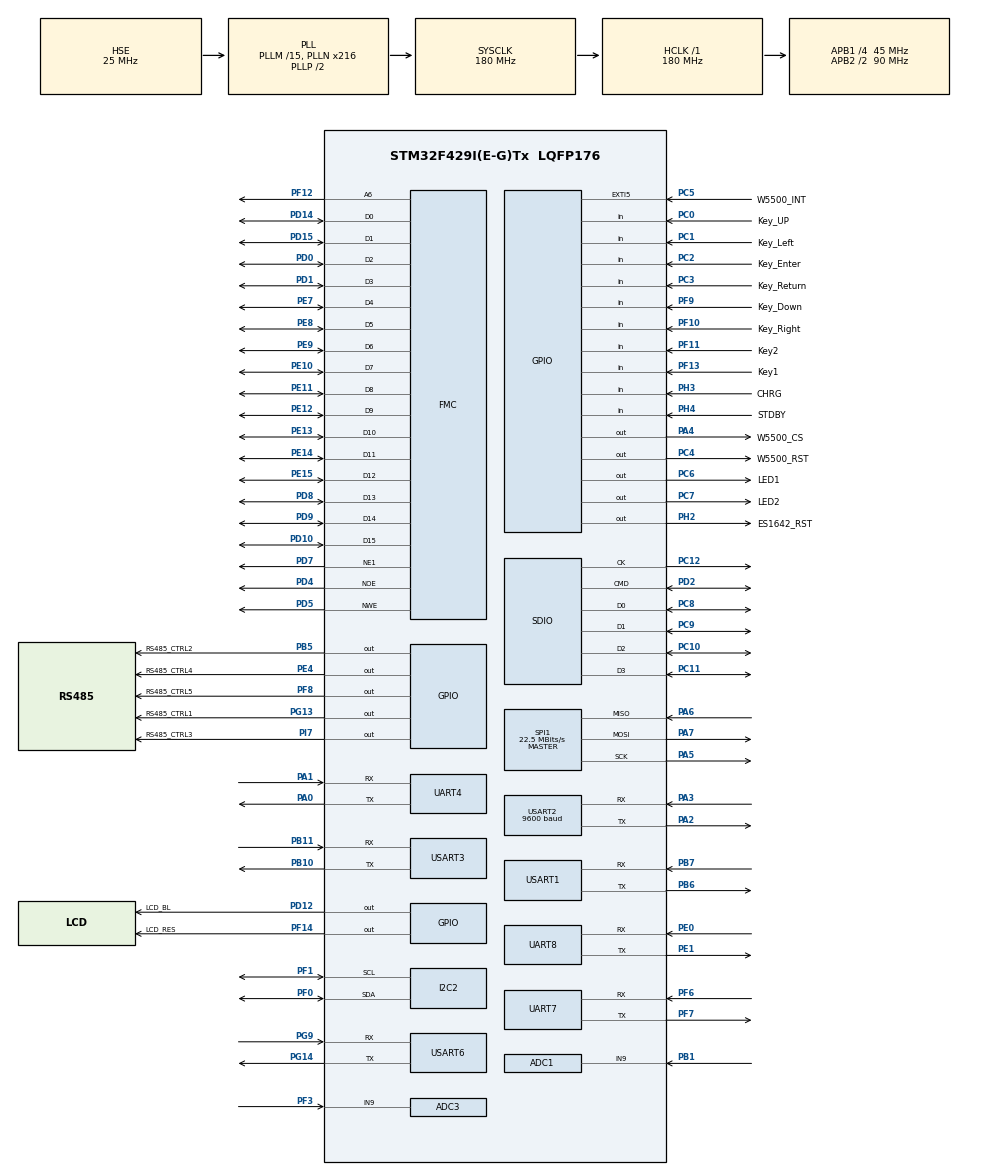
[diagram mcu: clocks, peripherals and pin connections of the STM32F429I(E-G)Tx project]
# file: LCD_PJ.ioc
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ADC1.Channel-1\#ChannelRegularConversion=ADC_CHANNEL_9
ADC1.NbrOfConversionFlag=1
ADC1.Rank-1\#ChannelRegularConversion=1
ADC1.SamplingTime-1\#ChannelRegularConversion=ADC_SAMPLETIME_144CYCLES
ADC1.master=1
ADC3.Channel-0\#ChannelRegularConversion=ADC_CHANNEL_9
ADC3.NbrOfConversionFlag=1
ADC3.Rank-0\#ChannelRegularConversion=1
ADC3.SamplingTime-0\#ChannelRegularConversion=ADC_SAMPLETIME_144CYCLES
Dma.MEMTOMEM.2.Direction=DMA_MEMORY_TO_MEMORY
Dma.MEMTOMEM.2.FIFOMode=DMA_FIFOMODE_ENABLE
Dma.MEMTOMEM.2.FIFOThreshold=DMA_FIFO_THRESHOLD_FULL
Dma.MEMTOMEM.2.Instance=DMA2_Stream4
Dma.MEMTOMEM.2.MemBurst=DMA_MBURST_INC8
Dma.MEMTOMEM.2.MemDataAlignment=DMA_MDATAALIGN_HALFWORD
Dma.MEMTOMEM.2.MemInc=DMA_MINC_DISABLE
Dma.MEMTOMEM.2.Mode=DMA_NORMAL
Dma.MEMTOMEM.2.PeriphBurst=DMA_PBURST_INC8
Dma.MEMTOMEM.2.PeriphDataAlignment=DMA_PDATAALIGN_HALFWORD
Dma.MEMTOMEM.2.PeriphInc=DMA_PINC_ENABLE
Dma.MEMTOMEM.2.Priority=DMA_PRIORITY_LOW
Dma.Request0=SDIO_RX
Dma.Request1=SDIO_TX
Dma.Request10=USART2_TX
Dma.Request11=SPI1_RX
Dma.Request12=SPI1_TX
Dma.Request2=MEMTOMEM
Dma.Request3=USART2_RX
Dma.Request4=USART3_RX
Dma.Request5=USART3_TX
Dma.Request6=USART6_RX
Dma.Request7=USART1_RX
Dma.Request8=UART4_RX
Dma.Request9=UART7_RX
Dma.SDIO_RX.0.Direction=DMA_PERIPH_TO_MEMORY
Dma.SDIO_RX.0.FIFOMode=DMA_FIFOMODE_ENABLE
Dma.SDIO_RX.0.FIFOThreshold=DMA_FIFO_THRESHOLD_FULL
Dma.SDIO_RX.0.Instance=DMA2_Stream6
Dma.SDIO_RX.0.MemBurst=DMA_MBURST_INC4
Dma.SDIO_RX.0.MemDataAlignment=DMA_MDATAALIGN_WORD
Dma.SDIO_RX.0.MemInc=DMA_MINC_ENABLE
Dma.SDIO_RX.0.Mode=DMA_PFCTRL
Dma.SDIO_RX.0.PeriphBurst=DMA_PBURST_INC4
Dma.SDIO_RX.0.PeriphDataAlignment=DMA_PDATAALIGN_WORD
Dma.SDIO_RX.0.PeriphInc=DMA_PINC_DISABLE
Dma.SDIO_RX.0.Priority=DMA_PRIORITY_MEDIUM
Dma.SDIO_TX.1.Direction=DMA_MEMORY_TO_PERIPH
Dma.SDIO_TX.1.FIFOMode=DMA_FIFOMODE_ENABLE
Dma.SDIO_TX.1.FIFOThreshold=DMA_FIFO_THRESHOLD_FULL
Dma.SDIO_TX.1.Instance=DMA2_Stream3
Dma.SDIO_TX.1.MemBurst=DMA_MBURST_INC4
Dma.SDIO_TX.1.MemDataAlignment=DMA_MDATAALIGN_WORD
Dma.SDIO_TX.1.MemInc=DMA_MINC_ENABLE
Dma.SDIO_TX.1.Mode=DMA_PFCTRL
Dma.SDIO_TX.1.PeriphBurst=DMA_PBURST_INC4
Dma.SDIO_TX.1.PeriphDataAlignment=DMA_PDATAALIGN_WORD
Dma.SDIO_TX.1.PeriphInc=DMA_PINC_DISABLE
Dma.SDIO_TX.1.Priority=DMA_PRIORITY_MEDIUM
Dma.SPI1_RX.11.Direction=DMA_PERIPH_TO_MEMORY
Dma.SPI1_RX.11.FIFOMode=DMA_FIFOMODE_DISABLE
Dma.SPI1_RX.11.Instance=DMA2_Stream0
Dma.SPI1_RX.11.MemDataAlignment=DMA_MDATAALIGN_BYTE
Dma.SPI1_RX.11.MemInc=DMA_MINC_ENABLE
Dma.SPI1_RX.11.Mode=DMA_NORMAL
Dma.SPI1_RX.11.PeriphDataAlignment=DMA_PDATAALIGN_BYTE
Dma.SPI1_RX.11.PeriphInc=DMA_PINC_DISABLE
Dma.SPI1_RX.11.Priority=DMA_PRIORITY_LOW
Dma.SPI1_TX.12.Direction=DMA_MEMORY_TO_PERIPH
Dma.SPI1_TX.12.FIFOMode=DMA_FIFOMODE_DISABLE
Dma.SPI1_TX.12.Instance=DMA2_Stream5
Dma.SPI1_TX.12.MemDataAlignment=DMA_MDATAALIGN_BYTE
Dma.SPI1_TX.12.MemInc=DMA_MINC_ENABLE
Dma.SPI1_TX.12.Mode=DMA_NORMAL
Dma.SPI1_TX.12.PeriphDataAlignment=DMA_PDATAALIGN_BYTE
Dma.SPI1_TX.12.PeriphInc=DMA_PINC_DISABLE
Dma.SPI1_TX.12.Priority=DMA_PRIORITY_LOW
Dma.UART4_RX.8.Direction=DMA_PERIPH_TO_MEMORY
Dma.UART4_RX.8.FIFOMode=DMA_FIFOMODE_DISABLE
Dma.UART4_RX.8.Instance=DMA1_Stream2
Dma.UART4_RX.8.MemDataAlignment=DMA_MDATAALIGN_BYTE
Dma.UART4_RX.8.MemInc=DMA_MINC_ENABLE
Dma.UART4_RX.8.Mode=DMA_NORMAL
Dma.UART4_RX.8.PeriphDataAlignment=DMA_PDATAALIGN_BYTE
Dma.UART4_RX.8.PeriphInc=DMA_PINC_DISABLE
Dma.UART4_RX.8.Priority=DMA_PRIORITY_LOW
Dma.UART7_RX.9.Direction=DMA_PERIPH_TO_MEMORY
Dma.UART7_RX.9.FIFOMode=DMA_FIFOMODE_DISABLE
Dma.UART7_RX.9.Instance=DMA1_Stream3
Dma.UART7_RX.9.MemDataAlignment=DMA_MDATAALIGN_BYTE
Dma.UART7_RX.9.MemInc=DMA_MINC_ENABLE
Dma.UART7_RX.9.Mode=DMA_NORMAL
Dma.UART7_RX.9.PeriphDataAlignment=DMA_PDATAALIGN_BYTE
Dma.UART7_RX.9.PeriphInc=DMA_PINC_DISABLE
Dma.UART7_RX.9.Priority=DMA_PRIORITY_LOW
Dma.USART1_RX.7.Direction=DMA_PERIPH_TO_MEMORY
Dma.USART1_RX.7.FIFOMode=DMA_FIFOMODE_DISABLE
Dma.USART1_RX.7.Instance=DMA2_Stream2
Dma.USART1_RX.7.MemDataAlignment=DMA_MDATAALIGN_BYTE
Dma.USART1_RX.7.MemInc=DMA_MINC_ENABLE
Dma.USART1_RX.7.Mode=DMA_NORMAL
Dma.USART1_RX.7.PeriphDataAlignment=DMA_PDATAALIGN_BYTE
Dma.USART1_RX.7.PeriphInc=DMA_PINC_DISABLE
Dma.USART1_RX.7.Priority=DMA_PRIORITY_LOW
Dma.USART2_RX.3.Direction=DMA_PERIPH_TO_MEMORY
Dma.USART2_RX.3.FIFOMode=DMA_FIFOMODE_DISABLE
Dma.USART2_RX.3.Instance=DMA1_Stream5
Dma.USART2_RX.3.MemDataAlignment=DMA_MDATAALIGN_BYTE
Dma.USART2_RX.3.MemInc=DMA_MINC_ENABLE
Dma.USART2_RX.3.Mode=DMA_NORMAL
Dma.USART2_RX.3.PeriphDataAlignment=DMA_PDATAALIGN_BYTE
Dma.USART2_RX.3.PeriphInc=DMA_PINC_DISABLE
Dma.USART2_RX.3.Priority=DMA_PRIORITY_LOW
Dma.USART2_TX.10.Direction=DMA_MEMORY_TO_PERIPH
Dma.USART2_TX.10.FIFOMode=DMA_FIFOMODE_DISABLE
Dma.USART2_TX.10.Instance=DMA1_Stream6
Dma.USART2_TX.10.MemDataAlignment=DMA_MDATAALIGN_BYTE
Dma.USART2_TX.10.MemInc=DMA_MINC_ENABLE
Dma.USART2_TX.10.Mode=DMA_NORMAL
Dma.USART2_TX.10.PeriphDataAlignment=DMA_PDATAALIGN_BYTE
Dma.USART2_TX.10.PeriphInc=DMA_PINC_DISABLE
Dma.USART2_TX.10.Priority=DMA_PRIORITY_LOW
Dma.USART3_RX.4.Direction=DMA_PERIPH_TO_MEMORY
Dma.USART3_RX.4.FIFOMode=DMA_FIFOMODE_DISABLE
Dma.USART3_RX.4.Instance=DMA1_Stream1
Dma.USART3_RX.4.MemDataAlignment=DMA_MDATAALIGN_BYTE
Dma.USART3_RX.4.MemInc=DMA_MINC_ENABLE
Dma.USART3_RX.4.Mode=DMA_NORMAL
Dma.USART3_RX.4.PeriphDataAlignment=DMA_PDATAALIGN_BYTE
Dma.USART3_RX.4.PeriphInc=DMA_PINC_DISABLE
Dma.USART3_RX.4.Priority=DMA_PRIORITY_LOW
Dma.USART3_TX.5.Direction=DMA_MEMORY_TO_PERIPH
Dma.USART3_TX.5.FIFOMode=DMA_FIFOMODE_DISABLE
Dma.USART3_TX.5.Instance=DMA1_Stream4
Dma.USART3_TX.5.MemDataAlignment=DMA_MDATAALIGN_BYTE
Dma.USART3_TX.5.MemInc=DMA_MINC_ENABLE
Dma.USART3_TX.5.Mode=DMA_NORMAL
Dma.USART3_TX.5.PeriphDataAlignment=DMA_PDATAALIGN_BYTE
Dma.USART3_TX.5.PeriphInc=DMA_PINC_DISABLE
Dma.USART3_TX.5.Priority=DMA_PRIORITY_LOW
Dma.USART6_RX.6.Direction=DMA_PERIPH_TO_MEMORY
Dma.USART6_RX.6.FIFOMode=DMA_FIFOMODE_DISABLE
Dma.USART6_RX.6.Instance=DMA2_Stream1
Dma.USART6_RX.6.MemDataAlignment=DMA_MDATAALIGN_BYTE
Dma.USART6_RX.6.MemInc=DMA_MINC_ENABLE
Dma.USART6_RX.6.Mode=DMA_NORMAL
Dma.USART6_RX.6.PeriphDataAlignment=DMA_PDATAALIGN_BYTE
Dma.USART6_RX.6.PeriphInc=DMA_PINC_DISABLE
Dma.USART6_RX.6.Priority=DMA_PRIORITY_LOW
FATFS._CODE_PAGE=936
FATFS._FS_EXFAT=0
FATFS._MAX_LFN=255
FATFS._MAX_SS=4096
FATFS._USE_LFN=2
FATFS._USE_MUTEX=0
FATFS._USE_TRIM=1
FMC.AddressSetupTime1=1
FMC.BusTurnAroundDuration1=0
FMC.DataSetupTime1=8
FREERTOS.BinarySemaphores01=at_sem,Dynamic,NULL,Depleted;at_mutex,Dynamic,NULL,Available;ES1642_send,Dynamic,NULL,Depleted;ES1642_mutex,Dynamic,NULL,Available
FREERTOS.Tasks01=defaultTask,19,512,StartDefaultTask,Default,NULL,Dynamic,NULL,NULL;LVGLTask,35,1024,lvgl_task,Default,NULL,Dynamic,NULL,NULL;A7680CTask,27,512,A7680C_Task,Default,NULL,Dynamic,NULL,NULL;W5500Task,17,1024,W5500_Task,As external,NULL,Dynamic,NULL,NULL;ES1642Task,29,512,ES1642_Task,Default,NULL,Dynamic,NULL,NULL;RTCTask,23,512,RTC_Task,Default,NULL,Dynamic,NULL,NULL;WeatherTask,13,512,Weather_Task,Default,NULL,Dynamic,NULL,NULL;RS485UARTProces,37,512,RS485_UART_ProcessTask,As external,NULL,Dynamic,NULL,NULL;DevicePollTask,21,640,DevicePoll_Task,Default,NULL,Dynamic,NULL,NULL
FREERTOS.Timers01=weatherTimer,Callback01,osTimerOnce,Default,NULL,Dynamic,NULL
FREERTOS.configTOTAL_HEAP_SIZE=30720
FREERTOS.configUSE_TICK_HOOK=1
IWDG.Prescaler=IWDG_PRESCALER_256
Mcu.Family=STM32F4
Mcu.Name=STM32F429I(E-G)Tx
Mcu.Package=LQFP176
NVIC.DMA1_Stream1_IRQn=true\:5\:0\:true\:false\:true\:true\:false\:true\:true
NVIC.DMA1_Stream2_IRQn=true\:5\:0\:true\:false\:true\:true\:false\:true\:true
NVIC.DMA1_Stream3_IRQn=true\:5\:0\:true\:false\:true\:true\:false\:true\:true
NVIC.DMA1_Stream4_IRQn=true\:5\:0\:true\:false\:true\:true\:false\:true\:true
NVIC.DMA1_Stream5_IRQn=true\:5\:0\:true\:false\:true\:true\:false\:true\:true
NVIC.DMA1_Stream6_IRQn=true\:5\:0\:false\:false\:true\:true\:false\:true\:true
NVIC.DMA2_Stream0_IRQn=true\:5\:0\:false\:false\:true\:true\:true\:true\:true
NVIC.DMA2_Stream1_IRQn=true\:5\:0\:true\:false\:true\:true\:false\:true\:true
NVIC.DMA2_Stream2_IRQn=true\:5\:0\:true\:false\:true\:true\:false\:true\:true
NVIC.DMA2_Stream3_IRQn=true\:5\:0\:true\:false\:true\:true\:false\:true\:true
NVIC.DMA2_Stream4_IRQn=true\:5\:0\:true\:false\:true\:true\:true\:true\:true
NVIC.DMA2_Stream5_IRQn=true\:5\:0\:false\:false\:true\:true\:false\:true\:true
NVIC.DMA2_Stream6_IRQn=true\:5\:0\:true\:false\:true\:true\:false\:true\:true
NVIC.EXTI9_5_IRQn=true\:5\:0\:true\:false\:true\:true\:true\:true\:true
NVIC.PriorityGroup=NVIC_PRIORITYGROUP_4
NVIC.SDIO_IRQn=true\:5\:0\:true\:false\:true\:true\:true\:true\:true
NVIC.SPI1_IRQn=true\:5\:0\:true\:false\:true\:true\:true\:true\:true
NVIC.TIM2_IRQn=true\:6\:0\:true\:false\:true\:true\:true\:true\:true
NVIC.TIM3_IRQn=true\:5\:0\:false\:false\:true\:true\:true\:true\:true
NVIC.TIM6_DAC_IRQn=true\:15\:0\:false\:false\:true\:false\:false\:true\:true
NVIC.TimeBase=TIM6_DAC_IRQn
NVIC.TimeBaseIP=TIM6
NVIC.UART4_IRQn=true\:5\:0\:true\:false\:true\:true\:true\:true\:true
NVIC.UART7_IRQn=true\:5\:0\:false\:false\:true\:true\:true\:true\:true
NVIC.UART8_IRQn=true\:5\:0\:true\:false\:true\:true\:true\:true\:true
NVIC.USART1_IRQn=true\:5\:0\:true\:false\:true\:true\:true\:true\:true
NVIC.USART2_IRQn=true\:5\:0\:true\:false\:true\:true\:true\:true\:true
NVIC.USART3_IRQn=true\:5\:0\:true\:false\:true\:true\:true\:true\:true
NVIC.USART6_IRQn=true\:5\:0\:true\:false\:true\:true\:true\:true\:true
PA0/WKUP.Mode=Asynchronous
PA0/WKUP.Signal=UART4_TX
PA1.Mode=Asynchronous
PA1.Signal=UART4_RX
PA13.Mode=Serial_Wire
PA13.Signal=SYS_JTMS-SWDIO
PA14.Mode=Serial_Wire
PA14.Signal=SYS_JTCK-SWCLK
PA2.Mode=Asynchronous
PA2.Signal=USART2_TX
PA3.Mode=Asynchronous
PA3.Signal=USART2_RX
PA4.GPIO_Label=W5500_CS
PA4.GPIO_Speed=GPIO_SPEED_FREQ_HIGH
PA4.PinState=GPIO_PIN_SET
PA4.Signal=GPIO_Output
PA5.Mode=Full_Duplex_Master
PA5.Signal=SPI1_SCK
PA6.Mode=Full_Duplex_Master
PA6.Signal=SPI1_MISO
PA7.Mode=Full_Duplex_Master
PA7.Signal=SPI1_MOSI
PB1.Signal=ADCx_IN9
PB10.Mode=Asynchronous
PB10.Signal=USART3_TX
PB11.Mode=Asynchronous
PB11.Signal=USART3_RX
PB5.GPIO_Label=RS485_CTRL2
PB5.GPIO_Speed=GPIO_SPEED_FREQ_HIGH
PB5.Signal=GPIO_Output
PB6.Mode=Asynchronous
PB6.Signal=USART1_TX
PB7.Mode=Asynchronous
PB7.Signal=USART1_RX
PC0.GPIO_Label=Key_UP
PC0.GPIO_PuPd=GPIO_PULLUP
PC0.Signal=GPIO_Input
PC1.GPIO_Label=Key_Left
PC1.GPIO_PuPd=GPIO_PULLUP
PC1.Signal=GPIO_Input
PC10.GPIO_PuPd=GPIO_PULLUP
PC10.Mode=SD_4_bits_Wide_bus
PC10.Signal=SDIO_D2
PC11.GPIO_PuPd=GPIO_PULLUP
PC11.Mode=SD_4_bits_Wide_bus
PC11.Signal=SDIO_D3
PC12.Mode=SD_4_bits_Wide_bus
PC12.Signal=SDIO_CK
PC14/OSC32_IN.Mode=LSE-External-Oscillator
PC14/OSC32_IN.Signal=RCC_OSC32_IN
PC15/OSC32_OUT.Mode=LSE-External-Oscillator
PC15/OSC32_OUT.Signal=RCC_OSC32_OUT
PC2.GPIO_Label=Key_Enter
PC2.GPIO_PuPd=GPIO_PULLUP
PC2.Signal=GPIO_Input
PC3.GPIO_Label=Key_Return
PC3.GPIO_PuPd=GPIO_PULLUP
PC3.Signal=GPIO_Input
PC4.GPIO_Label=W5500_RST
PC4.GPIO_Speed=GPIO_SPEED_FREQ_HIGH
PC4.PinState=GPIO_PIN_SET
PC4.Signal=GPIO_Output
PC5.GPIO_Label=W5500_INT
PC5.GPIO_ModeDefaultEXTI=GPIO_MODE_IT_FALLING
PC5.GPIO_PuPd=GPIO_PULLUP
PC5.Signal=GPXTI5
PC6.GPIO_Label=LED1
PC6.PinState=GPIO_PIN_SET
PC6.Signal=GPIO_Output
PC7.GPIO_Label=LED2
PC7.GPIO_Speed=GPIO_SPEED_FREQ_HIGH
PC7.PinState=GPIO_PIN_SET
PC7.Signal=GPIO_Output
PC8.GPIO_PuPd=GPIO_PULLUP
PC8.Mode=SD_4_bits_Wide_bus
PC8.Signal=SDIO_D0
PC9.GPIO_PuPd=GPIO_PULLUP
PC9.Mode=SD_4_bits_Wide_bus
PC9.Signal=SDIO_D1
PD0.Signal=FMC_D2_DA2
PD1.Signal=FMC_D3_DA3
PD10.Signal=FMC_D15_DA15
PD12.GPIO_Label=LCD_BL
PD12.GPIO_Speed=GPIO_SPEED_FREQ_HIGH
PD12.Signal=GPIO_Output
PD14.Signal=FMC_D0_DA0
PD15.Signal=FMC_D1_DA1
PD2.GPIO_PuPd=GPIO_PULLUP
PD2.Mode=SD_4_bits_Wide_bus
PD2.Signal=SDIO_CMD
PD4.Signal=FMC_NOE
PD5.Signal=FMC_NWE
PD7.Mode=NorPsramChipSelect1_1
PD7.Signal=FMC_NE1
PD8.Signal=FMC_D13_DA13
PD9.Signal=FMC_D14_DA14
PE0.Mode=Asynchronous
PE0.Signal=UART8_RX
PE1.Mode=Asynchronous
PE1.Signal=UART8_TX
PE10.Signal=FMC_D7_DA7
PE11.Signal=FMC_D8_DA8
PE12.Signal=FMC_D9_DA9
PE13.Signal=FMC_D10_DA10
PE14.Signal=FMC_D11_DA11
PE15.Signal=FMC_D12_DA12
PE4.GPIO_Label=RS485_CTRL4
PE4.Signal=GPIO_Output
PE7.Signal=FMC_D4_DA4
PE8.Signal=FMC_D5_DA5
PE9.Signal=FMC_D6_DA6
PF0.Mode=I2C
PF0.Signal=I2C2_SDA
PF1.Mode=I2C
PF1.Signal=I2C2_SCL
PF10.GPIO_Label=Key_Right
PF10.GPIO_PuPd=GPIO_PULLUP
PF10.Signal=GPIO_Input
PF11.GPIO_Label=Key2
PF11.GPIO_PuPd=GPIO_PULLUP
PF11.Signal=GPIO_Input
PF12.Signal=FMC_A6
PF13.GPIO_Label=Key1
PF13.GPIO_PuPd=GPIO_PULLUP
PF13.Signal=GPIO_Input
PF14.GPIO_Label=LCD_RES
PF14.GPIO_Speed=GPIO_SPEED_FREQ_HIGH
PF14.PinState=GPIO_PIN_SET
PF14.Signal=GPIO_Output
PF3.Mode=IN9
PF3.Signal=ADC3_IN9
PF6.Mode=Asynchronous
PF6.Signal=UART7_RX
PF7.Mode=Asynchronous
PF7.Signal=UART7_TX
PF8.GPIO_Label=RS485_CTRL5
PF8.Signal=GPIO_Output
PF9.GPIO_Label=Key_Down
PF9.GPIO_PuPd=GPIO_PULLUP
PF9.Signal=GPIO_Input
PG13.GPIO_Label=RS485_CTRL1
PG13.GPIO_Speed=GPIO_SPEED_FREQ_HIGH
PG13.Signal=GPIO_Output
PG14.Mode=Asynchronous
PG14.Signal=USART6_TX
PG9.Mode=Asynchronous
PG9.Signal=USART6_RX
PH0/OSC_IN.Mode=HSE-External-Oscillator
PH0/OSC_IN.Signal=RCC_OSC_IN
PH1/OSC_OUT.Mode=HSE-External-Oscillator
PH1/OSC_OUT.Signal=RCC_OSC_OUT
PH2.GPIO_Label=ES1642_RST
PH2.GPIO_Speed=GPIO_SPEED_FREQ_HIGH
PH2.PinState=GPIO_PIN_SET
PH2.Signal=GPIO_Output
PH3.GPIO_Label=CHRG
PH3.GPIO_PuPd=GPIO_PULLUP
PH3.Signal=GPIO_Input
PH4.GPIO_Label=STDBY
PH4.GPIO_PuPd=GPIO_PULLUP
PH4.Signal=GPIO_Input
PI7.GPIO_Label=RS485_CTRL3
PI7.Signal=GPIO_Output
ProjectManager.HeapSize=0x2000
ProjectManager.StackSize=0x4000
ProjectManager.TargetToolchain=MDK-ARM V5.32
RCC.48MHZClocksFreq_Value=45000000
RCC.AHBFreq_Value=180000000
RCC.APB1CLKDivider=RCC_HCLK_DIV4
RCC.APB1Freq_Value=45000000
RCC.APB1TimFreq_Value=90000000
RCC.APB2CLKDivider=RCC_HCLK_DIV2
RCC.APB2Freq_Value=90000000
RCC.APB2TimFreq_Value=180000000
RCC.CortexFreq_Value=180000000
RCC.HCLKFreq_Value=180000000
RCC.HSE_VALUE=25000000
RCC.HSI_VALUE=16000000
RCC.PLLM=15
RCC.PLLN=216
RCC.PLLQ=8
RCC.PLLSAIDivR=RCC_PLLSAIDIVR_4
RCC.PLLSAIN=60
RCC.PLLSourceVirtual=RCC_PLLSOURCE_HSE
RCC.SYSCLKFreq_VALUE=180000000
RCC.SYSCLKSource=RCC_SYSCLKSOURCE_PLLCLK
RCC.VCOOutputFreq_Value=360000000
SDIO.ClockDiv=8
SDIO.HardwareFlowControl=SDIO_HARDWARE_FLOW_CONTROL_DISABLE
SH.ADCx_IN9.0=ADC1_IN9,IN9
SH.FMC_A6.0=FMC_A6,A6_1
SH.FMC_D0_DA0.0=FMC_D0,16b-d1
SH.FMC_D10_DA10.0=FMC_D10,16b-d1
SH.FMC_D11_DA11.0=FMC_D11,16b-d1
SH.FMC_D12_DA12.0=FMC_D12,16b-d1
SH.FMC_D13_DA13.0=FMC_D13,16b-d1
SH.FMC_D14_DA14.0=FMC_D14,16b-d1
SH.FMC_D15_DA15.0=FMC_D15,16b-d1
SH.FMC_D1_DA1.0=FMC_D1,16b-d1
SH.FMC_D2_DA2.0=FMC_D2,16b-d1
SH.FMC_D3_DA3.0=FMC_D3,16b-d1
SH.FMC_D4_DA4.0=FMC_D4,16b-d1
SH.FMC_D5_DA5.0=FMC_D5,16b-d1
SH.FMC_D6_DA6.0=FMC_D6,16b-d1
SH.FMC_D7_DA7.0=FMC_D7,16b-d1
SH.FMC_D8_DA8.0=FMC_D8,16b-d1
SH.FMC_D9_DA9.0=FMC_D9,16b-d1
SH.FMC_NOE.0=FMC_NOE,Lcd1
SH.FMC_NWE.0=FMC_NWE,Lcd1
SPI1.BaudRatePrescaler=SPI_BAUDRATEPRESCALER_4
SPI1.CalculateBaudRate=22.5 MBits/s
SPI1.Direction=SPI_DIRECTION_2LINES
SPI1.Mode=SPI_MODE_MASTER
SPI1.VirtualType=VM_MASTER
TIM2.Period=1000-1
TIM2.Prescaler=90-1
TIM3.Period=59999
TIM3.Prescaler=44999
UART4.VirtualMode=Asynchronous
UART7.VirtualMode=Asynchronous
UART8.VirtualMode=Asynchronous
USART1.VirtualMode=VM_ASYNC
USART2.BaudRate=9600
USART2.VirtualMode=VM_ASYNC
USART3.VirtualMode=VM_ASYNC
USART6.VirtualMode=VM_ASYNC
VP_CRC_VS_CRC.Mode=CRC_Activate
VP_FATFS_VS_SDIO.Mode=SDIO
VP_FREERTOS_VS_CMSIS_V2.Mode=CMSIS_V2
VP_IWDG_VS_IWDG.Mode=IWDG_Activate
VP_RTC_VS_RTC_Activate.Mode=RTC_Enabled
VP_SYS_VS_tim6.Mode=TIM6
VP_TIM2_VS_ClockSourceINT.Mode=Internal
VP_TIM3_VS_ClockSourceINT.Mode=Internal
board=custom

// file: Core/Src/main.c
/* USER CODE BEGIN Header */
/**
  ******************************************************************************
  * @file           : main.c
  * @brief          : Main program body
  ******************************************************************************
  * @attention
  *
  * Copyright (c) 2026 STMicroelectronics.
  * All rights reserved.
  *
  * This software is licensed under terms that can be found in the LICENSE file
  * in the root directory of this software component.
  * If no LICENSE file comes with this software, it is provided AS-IS.
  *
  ******************************************************************************
  */
/* USER CODE END Header */
#include "main.h"
#include "cmsis_os.h"
#include "adc.h"
#include "crc.h"
#include "dma.h"
#include "fatfs.h"
#include "i2c.h"
#include "iwdg.h"
#include "rtc.h"
#include "sdio.h"
#include "spi.h"
#include "tim.h"
#include "usart.h"
#include "gpio.h"
#include "fmc.h"

/* USER CODE BEGIN Includes */
#include "lv_hal_tick.h"
#include "stdio.h"
#include "wiz_interface.h"
#include "lv_port_disp.h"
#include "rs485_usart.h"
#include "battery.h"
#include "bank_switch.h"
#include "ota_upgrade.h"
/* USER CODE END Includes */

void SystemClock_Config(void);
void MX_FREERTOS_Init(void);

int main(void)
{

  /* MCU Configuration--------------------------------------------------------*/

  /* Reset of all peripherals, Initializes the Flash interface and the Systick. */
  HAL_Init();

  /* Configure the system clock */
  SystemClock_Config();

  /* Initialize all configured peripherals */
  MX_GPIO_Init();
  MX_DMA_Init();
  MX_USART1_UART_Init();
  MX_FMC_Init();
  MX_SDIO_SD_Init();
  MX_FATFS_Init();
  MX_SPI1_Init();
  MX_TIM2_Init();
  MX_USART3_UART_Init();
  MX_I2C2_Init();
  MX_USART2_UART_Init();
  MX_TIM3_Init();
  MX_UART4_Init();
  MX_UART7_Init();
  MX_UART8_Init();
  MX_USART6_UART_Init();
  MX_ADC3_Init();
  MX_ADC1_Init();
  MX_CRC_Init();
  MX_IWDG_Init();
  MX_RTC_Init();
  /* USER CODE BEGIN 2 */
	Battery_Init();
	RS485_USART_Init_All();
  /* OTA: check trial boot / rollback (must be after MX_RTC_Init) */
  BANK_EnableDualBank();// 启用双Bank模式 (如果尚未启用)
  OTA_BootCheck();// 回滚检查（如果 magic=PENDING）
  OTA_Init();// 初始化 OTA 状态变量

	Battery_UpdateCache();//更新一次电量缓存
	Solar_UpdateCache();//更新一次太阳能电压缓存
	//注册搬运图像数据完成回调函数
	HAL_DMA_RegisterCallback(&hdma_memtomem_dma2_stream4, HAL_DMA_XFER_CPLT_CB_ID, LVGL_LCD_FSMC_DMA_pCallback);
  /* USER CODE END 2 */

  /* Init scheduler */
  osKernelInitialize();  /* Call init function for freertos objects (in cmsis_os2.c) */
  MX_FREERTOS_Init();

  /* Start scheduler */
  osKernelStart();

  /* We should never get here as control is now taken by the scheduler */

  /* Infinite loop */
  while (1)
  {

  }
}

void SystemClock_Config(void)
{
  RCC_OscInitTypeDef RCC_OscInitStruct = {0};
  RCC_ClkInitTypeDef RCC_ClkInitStruct = {0};

  /** Configure the main internal regulator output voltage
  */
  __HAL_RCC_PWR_CLK_ENABLE();
  __HAL_PWR_VOLTAGESCALING_CONFIG(PWR_REGULATOR_VOLTAGE_SCALE1);

  /** Initializes the RCC Oscillators according to the specified parameters
  * in the RCC_OscInitTypeDef structure.
  */
  RCC_OscInitStruct.OscillatorType = RCC_OSCILLATORTYPE_LSI|RCC_OSCILLATORTYPE_HSE;
  RCC_OscInitStruct.HSEState = RCC_HSE_ON;
  RCC_OscInitStruct.LSIState = RCC_LSI_ON;
  RCC_OscInitStruct.PLL.PLLState = RCC_PLL_ON;
  RCC_OscInitStruct.PLL.PLLSource = RCC_PLLSOURCE_HSE;
  RCC_OscInitStruct.PLL.PLLM = 15;
  RCC_OscInitStruct.PLL.PLLN = 216;
  RCC_OscInitStruct.PLL.PLLP = RCC_PLLP_DIV2;
  RCC_OscInitStruct.PLL.PLLQ = 8;
  if (HAL_RCC_OscConfig(&RCC_OscInitStruct) != HAL_OK)
  {
    Error_Handler();
  }

  /** Activate the Over-Drive mode
  */
  if (HAL_PWREx_EnableOverDrive() != HAL_OK)
  {
    Error_Handler();
  }

  /** Initializes the CPU, AHB and APB buses clocks
  */
  RCC_ClkInitStruct.ClockType = RCC_CLOCKTYPE_HCLK|RCC_CLOCKTYPE_SYSCLK
                              |RCC_CLOCKTYPE_PCLK1|RCC_CLOCKTYPE_PCLK2;
  RCC_ClkInitStruct.SYSCLKSource = RCC_SYSCLKSOURCE_PLLCLK;
  RCC_ClkInitStruct.AHBCLKDivider = RCC_SYSCLK_DIV1;
  RCC_ClkInitStruct.APB1CLKDivider = RCC_HCLK_DIV4;
  RCC_ClkInitStruct.APB2CLKDivider = RCC_HCLK_DIV2;

  if (HAL_RCC_ClockConfig(&RCC_ClkInitStruct, FLASH_LATENCY_5) != HAL_OK)
  {
    Error_Handler();
  }
}

/* USER CODE BEGIN 4 */
void vApplicationTickHook(void)
{
		// 先调用 lv_tick_inc 再调用 lv_task_handler
    lv_tick_inc(1);  // 告诉 LVGL 过了 1 毫秒
}

/* USER CODE END 4 */

void HAL_TIM_PeriodElapsedCallback(TIM_HandleTypeDef *htim)
{
  if (htim->Instance == TIM6)
  {
    HAL_IncTick();
  }
  /* USER CODE BEGIN Callback 1 */
	if (htim->Instance == TIM2)
	{
		wiz_timer_handler();
	}
	if (htim->Instance == TIM3)
	{
		HAL_TIM_Base_Stop_IT(&htim3);//停止定时器,并关闭背光灯
		HAL_GPIO_WritePin(LCD_BL_GPIO_Port, LCD_BL_Pin, GPIO_PIN_RESET);
	}
  /* USER CODE END Callback 1 */
}

void Error_Handler(void)
{
  __disable_irq();
  while (1)
  {
  }
}

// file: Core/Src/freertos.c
/* USER CODE BEGIN Header */
/**
  ******************************************************************************
  * File Name          : freertos.c
  * Description        : Code for freertos applications
  ******************************************************************************
  * @attention
  *
  * Copyright (c) 2026 STMicroelectronics.
  * All rights reserved.
  *
  * This software is licensed under terms that can be found in the LICENSE file
  * in the root directory of this software component.
  * If no LICENSE file comes with this software, it is provided AS-IS.
  *
  ******************************************************************************
  */
/* USER CODE END Header */

#include "FreeRTOS.h"
#include "task.h"
#include "main.h"
#include "cmsis_os.h"

/* USER CODE BEGIN Includes */
#include "stdio.h"
#include "message_buffer.h"
#include "lvgl.h"
#include "lv_port_disp.h"
#include "lv_port_indev.h"
#include "lv_port_fs.h"
#include "key.h"
#include "gui_guider.h"           // Gui Guider 生成的界面和控件的声明
#include "events_init.h"          // Gui Guider 生成的初始化事件、回调函数
#include "sdio.h"
#include "fatfs.h"
#include "custom.h"
#include "a7680c.h"
#include "a7680c_netmgr.h"
#include "a7680c_at.h"
#include "a7680c_mqtt.h"
#include "rx8025t_example.h"
#include "es1642.h"
#include "es1642_usage_guide.h"
#include "device_manager.h"
#include "user_data_manager.h"
#include "a7680c_http.h"
#include "rs485_usart.h"
#include "battery.h"
#include "mppt.h"
#include "user_main.h"
#include "ota_upgrade.h"
#include "tcp_cmd_handler.h"
lv_ui  guider_ui;                     // 定义 界面对象
extern lv_group_t * g_keypad_group;		//声明全局group
WeatherCurrent_t weather_data = {0};//存储天气代码的结构体

/* LVGL互斥锁: 保护多任务对LVGL API的并发访问 */
osMutexId_t lvgl_mutex = NULL;
/* 文件系统互斥锁: 保护共享SDFile/SDFatFS的并发访问 */
osMutexId_t fs_mutex = NULL;
/* USER CODE END Includes */

/* USER CODE BEGIN PTD */
MessageBufferHandle_t uart2Message;//es1642消息缓冲区句柄
MessageBufferHandle_t uart3Message;//a7680c消息缓冲区句柄
/* USER CODE END PTD */

/* USER CODE BEGIN PM */
void SDCardInfo(void)
{
    HAL_SD_CardInfoTypeDef pCardInfo = {0};                    // SD卡信息结构体
    uint8_t status = HAL_SD_GetCardState(&hsd);                // SD卡状态标志值
    if (status == HAL_SD_CARD_TRANSFER)
    {
        HAL_SD_GetCardInfo(&hsd, &pCardInfo);                  // 获取 SD 卡的信息
        printf("\r\n");
        printf("*** 获取SD卡信息 *** \r\n");
        printf("卡类型：%d \r\n", pCardInfo.CardType);         // 类型返回：0-SDSC、1-SDHC/SDXC、3-SECURED
        printf("卡版本：%d \r\n", pCardInfo.CardVersion);      // 版本返回：0-CARD_V1、1-CARD_V2
        printf("块数量：%d \r\n", pCardInfo.BlockNbr);         // 可用的块数量
        printf("块大小：%d \r\n", pCardInfo.BlockSize);        // 每个块的大小; 单位：字节
        printf("卡容量：%lluMB \r\n", ((uint64_t)pCardInfo.BlockSize * pCardInfo.BlockNbr) / 1024 / 1024);  // 计算卡的容量; 单位：GB
		}
}
  /* USER CODE END StartDefaultTask */

/* USER CODE END PM */

/* Definitions for defaultTask */
osThreadId_t defaultTaskHandle;
const osThreadAttr_t defaultTask_attributes = {
  .name = "defaultTask",
  .stack_size = 512 * 4,
  .priority = (osPriority_t) osPriorityBelowNormal3,
};
/* Definitions for LVGLTask */
osThreadId_t LVGLTaskHandle;
const osThreadAttr_t LVGLTask_attributes = {
  .name = "LVGLTask",
  .stack_size = 1024 * 4,
  .priority = (osPriority_t) osPriorityAboveNormal3,
};
/* Definitions for A7680CTask */
osThreadId_t A7680CTaskHandle;
const osThreadAttr_t A7680CTask_attributes = {
  .name = "A7680CTask",
  .stack_size = 512 * 4,
  .priority = (osPriority_t) osPriorityNormal3,
};
/* Definitions for W5500Task */
osThreadId_t W5500TaskHandle;
const osThreadAttr_t W5500Task_attributes = {
  .name = "W5500Task",
  .stack_size = 1024 * 4,
  .priority = (osPriority_t) osPriorityBelowNormal1,
};
/* Definitions for ES1642Task */
osThreadId_t ES1642TaskHandle;
const osThreadAttr_t ES1642Task_attributes = {
  .name = "ES1642Task",
  .stack_size = 512 * 4,
  .priority = (osPriority_t) osPriorityNormal5,
};
/* Definitions for RTCTask */
osThreadId_t RTCTaskHandle;
const osThreadAttr_t RTCTask_attributes = {
  .name = "RTCTask",
  .stack_size = 512 * 4,
  .priority = (osPriority_t) osPriorityBelowNormal7,
};
/* Definitions for WeatherTask */
osThreadId_t WeatherTaskHandle;
const osThreadAttr_t WeatherTask_attributes = {
  .name = "WeatherTask",
  .stack_size = 512 * 4,
  .priority = (osPriority_t) osPriorityLow5,
};
/* Definitions for RS485UARTProces */
osThreadId_t RS485UARTProcesHandle;
const osThreadAttr_t RS485UARTProces_attributes = {
  .name = "RS485UARTProces",
  .stack_size = 512 * 4,
  .priority = (osPriority_t) osPriorityAboveNormal5,
};
/* Definitions for DevicePollTask */
osThreadId_t DevicePollTaskHandle;
const osThreadAttr_t DevicePollTask_attributes = {
  .name = "DevicePollTask",
  .stack_size = 640 * 4,
  .priority = (osPriority_t) osPriorityBelowNormal5,
};
/* Definitions for weatherTimer */
osTimerId_t weatherTimerHandle;
const osTimerAttr_t weatherTimer_attributes = {
  .name = "weatherTimer"
};
/* Definitions for at_sem */
osSemaphoreId_t at_semHandle;
const osSemaphoreAttr_t at_sem_attributes = {
  .name = "at_sem"
};
/* Definitions for at_mutex */
osSemaphoreId_t at_mutexHandle;
const osSemaphoreAttr_t at_mutex_attributes = {
  .name = "at_mutex"
};
/* Definitions for ES1642_send */
osSemaphoreId_t ES1642_sendHandle;
const osSemaphoreAttr_t ES1642_send_attributes = {
  .name = "ES1642_send"
};
/* Definitions for ES1642_mutex */
osSemaphoreId_t ES1642_mutexHandle;
const osSemaphoreAttr_t ES1642_mutex_attributes = {
  .name = "ES1642_mutex"
};

void StartDefaultTask(void *argument);
void lvgl_task(void *argument);
void A7680C_Task(void *argument);
extern void W5500_Task(void *argument);
void ES1642_Task(void *argument);
void RTC_Task(void *argument);
void Weather_Task(void *argument);
extern void RS485_UART_ProcessTask(void *argument);
void DevicePoll_Task(void *argument);
void Callback01(void *argument);

void MX_FREERTOS_Init(void); /* (MISRA C 2004 rule 8.1) */

/* Hook prototypes */
void vApplicationTickHook(void);

/* USER CODE BEGIN 3 */
__weak void vApplicationTickHook( void )
{
   /* This function will be called by each tick interrupt if
   configUSE_TICK_HOOK is set to 1 in FreeRTOSConfig.h. User code can be
   added here, but the code must not attempt to block, and only the interrupt safe FreeRTOS API
   functions can be used (those that end in FromISR()). */
}
/* USER CODE END 3 */

void MX_FREERTOS_Init(void) {

  /* USER CODE BEGIN RTOS_MUTEX */
  /* 创建LVGL互斥锁 */
  lvgl_mutex = osMutexNew(NULL);
  /* 创建文件系统互斥锁 */
  fs_mutex = osMutexNew(NULL);
  /* USER CODE END RTOS_MUTEX */

  /* Create the semaphores(s) */
  /* creation of at_sem */
  at_semHandle = osSemaphoreNew(1, 0, &at_sem_attributes);

  /* creation of at_mutex */
  at_mutexHandle = osSemaphoreNew(1, 1, &at_mutex_attributes);

  /* creation of ES1642_send */
  ES1642_sendHandle = osSemaphoreNew(1, 0, &ES1642_send_attributes);

  /* creation of ES1642_mutex */
  ES1642_mutexHandle = osSemaphoreNew(1, 1, &ES1642_mutex_attributes);

  /* Create the timer(s) */
  /* creation of weatherTimer */
  weatherTimerHandle = osTimerNew(Callback01, osTimerOnce, NULL, &weatherTimer_attributes);

  /* USER CODE BEGIN RTOS_QUEUES */
  /* add queues, ... */
	uart2Message = xMessageBufferCreate(ES1642_RX_BUF_SIZE);
	if(uart2Message == NULL)
	{
			// 创建失败（内存不足）
			Error_Handler();
	}
	uart3Message = xMessageBufferCreate(AT_MSG_BUFFER_SIZE);
	if(uart3Message == NULL)
	{
			// 创建失败（内存不足）
			Error_Handler();
	}
  /* USER CODE END RTOS_QUEUES */

  /* Create the thread(s) */
  /* creation of defaultTask */
  defaultTaskHandle = osThreadNew(StartDefaultTask, NULL, &defaultTask_attributes);

  /* creation of LVGLTask */
  LVGLTaskHandle = osThreadNew(lvgl_task, NULL, &LVGLTask_attributes);

  /* creation of A7680CTask */
  A7680CTaskHandle = osThreadNew(A7680C_Task, NULL, &A7680CTask_attributes);

  /* creation of W5500Task */
  W5500TaskHandle = osThreadNew(W5500_Task, NULL, &W5500Task_attributes);

  /* creation of ES1642Task */
  ES1642TaskHandle = osThreadNew(ES1642_Task, NULL, &ES1642Task_attributes);

  /* creation of RTCTask */
  RTCTaskHandle = osThreadNew(RTC_Task, NULL, &RTCTask_attributes);

  /* creation of WeatherTask */
  WeatherTaskHandle = osThreadNew(Weather_Task, NULL, &WeatherTask_attributes);

  /* creation of RS485UARTProces */
  RS485UARTProcesHandle = osThreadNew(RS485_UART_ProcessTask, NULL, &RS485UARTProces_attributes);

  /* creation of DevicePollTask */
  DevicePollTaskHandle = osThreadNew(DevicePoll_Task, NULL, &DevicePollTask_attributes);

}

/* USER CODE BEGIN Header_StartDefaultTask */
/**
  * @brief  A7680C模块管理任务
  * @param  argument: Not used
  * @retval None
  * @note   网络初始化/健康检查逻辑已封装到 a7680c_netmgr.c
  */
/* USER CODE END Header_StartDefaultTask */
void StartDefaultTask(void *argument)
{
  /* USER CODE BEGIN StartDefaultTask */
//	A7680C_NetManager_Init(weatherTimerHandle);

	/* OTA: feed watchdog on startup, confirm upgrade if pending */
	OTA_FeedWatchdog();
	osDelay(5000);
	OTA_FeedWatchdog();
	OTA_ConfirmIfPending();

  /* Infinite loop */
  for(;;)
  {
		OTA_FeedWatchdog();
		HAL_GPIO_TogglePin(LED1_GPIO_Port, LED1_Pin);
		HAL_GPIO_TogglePin(LED2_GPIO_Port, LED2_Pin);

//		uint32_t delay = A7680C_NetManager_Process();
//		if (delay > 0)
//		{
//			osDelay(delay);
//		}
		osDelay(1000);
  }
  /* USER CODE END StartDefaultTask */
}

void lvgl_task(void *argument)
{
  /* USER CODE BEGIN lvgl_task */
	lv_init();  						/*初始化LVGL图形库*/
	g_keypad_group = lv_group_create();//给全局group分配空间
	lv_port_disp_init();		/* lvgl显示接口初始化,放在lv_init()的后面 */
	lv_port_indev_init();   /* lvgl输入接口初始化,放在lv_init()的后面 */
	lv_port_fs_init();   		/* lvgl文件系统接口初始化,放在lv_init()的后面 */
	printf("LVGL Version: %d.%d.%d\r\n", LVGL_VERSION_MAJOR, LVGL_VERSION_MINOR, LVGL_VERSION_PATCH);

	// 文件系统初始化完成之后读取设备表文件加载到RAM中
	device_manager_init();

	// 从SD卡加载主机MAC地址(优先于ES1642_ReadMac, 开机即可用)
	host_mac_load();

	// 从SD卡加载所有已入网设备的用电量数据到RAM缓存（在UI显示之前完成）
	user_detail_cache_init();

	// 从SD卡加载太阳能发电量数据到RAM（文件系统初始化完成后）
	solar_energy_init();

	// 从TF卡读取TCP服务器IP/Port配置 (在W5500_Task连接之前完成)
	tcp_config_load();

	// 从SD卡加载备注信息到RAM
	remark_info_load();

	// 从SD卡加载楼栋号到RAM
	building_no_load();

	/* USER CODE END 2 */
	//自己设计的图形窗口
	setup_ui(&guider_ui);           // 初始化 UI
	events_init(&guider_ui);       // 初始化 事件
	custom_init(&guider_ui);			// 你自己的逻辑

	/* UI初始化完成，通知RTC_Task可以操作LVGL了 */
	osThreadFlagsSet(RTCTaskHandle, 0x02);
	printf("LVGL UI初始化完成\r\n");

  /* Infinite loop */
  for(;;)
  {
		if(lvgl_mutex) osMutexAcquire(lvgl_mutex, osWaitForever);
		lv_timer_handler();  // 处理 LVGL 任务
		if(lvgl_mutex) osMutexRelease(lvgl_mutex);
		osDelay(5);
  }
  /* USER CODE END lvgl_task */
}

void A7680C_Task(void *argument)
{
  /* USER CODE BEGIN A7680C_Task */
	uint8_t recv_buf[256];
	A7680C_Init();
  /* Infinite loop */
  for(;;)
  {
		size_t len = xMessageBufferReceive(uart3Message, recv_buf, sizeof(recv_buf), portMAX_DELAY);
		if(len > 0)
		{
				//调用流式拼接函数
				at_process_data(recv_buf, len);
		}
  }
  /* USER CODE END A7680C_Task */
}

void ES1642_Task(void *argument)
{
  /* USER CODE BEGIN ES1642_Task */
	static uint8_t buf[ES1642_MAX_FRAME_LEN];
	// 初始化ES1642模块
	if (ES1642_InitModule() != 0)
	{
			Error_Handler();
	}
  /* Infinite loop */
  for(;;)
  {
		//等待消息缓冲区有消息包，然后读取一包数据,xMessageBufferReceive会释放cpu,只要消息缓冲区有消息就会解除阻塞向下执行
		size_t n = xMessageBufferReceive(uart2Message, buf, sizeof(buf), pdMS_TO_TICKS(5000));
		if(n)
		{
				ES1642_ProcessCompleteFrame(&g_es1642_handle,buf,n);
		}
		else
		{
				// 超时，检查UART是否还活着
				if (huart2.RxState != HAL_UART_STATE_BUSY_RX)
				{
						printf("huart2DMA已死，重启DMA");
						// DMA接收已死，重新启动
						HAL_UARTEx_ReceiveToIdle_DMA(&huart2, g_es1642_rx_buf, sizeof(g_es1642_rx_buf));
						__HAL_DMA_DISABLE_IT(huart2.hdmarx, DMA_IT_HT);
				}
				continue;
		}
  }
  /* USER CODE END ES1642_Task */
}

/* USER CODE BEGIN Header_RTC_Task */
/**
* @brief Function implementing the RTCTask thread.
* @param argument: Not used
* @retval None
*
* 职责（精简版，AT模块管理已移至StartDefaultTask）:
* 1. 初始化外部RTC芯片RX8025T
* 2. 跳转到home界面
* 3. 启动天气定时器
* 4. 循环更新RTC时间显示
*/
/* USER CODE END Header_RTC_Task */
void RTC_Task(void *argument)
{
  /* USER CODE BEGIN RTC_Task */
	if (RX8025T_InitAndDisplay() != HAL_OK) printf("外部RTC时钟通信失败\r\n");

	/* 等待LVGL UI初始化完成（由lvgl_task发送0x02标志） */
	osThreadFlagsWait(0x02, osFlagsWaitAny, osWaitForever);
	printf("RTCTask: LVGL UI已就绪\r\n");
	osDelay(1500);

	/* 跳转到home界面 (获取互斥锁保护LVGL操作) */
	if(lvgl_mutex) osMutexAcquire(lvgl_mutex, osWaitForever);
	ui_load_scr_animation(&guider_ui, &guider_ui.screen_user_home,
			guider_ui.screen_user_home_del, &guider_ui.Startup_screen_del,
			setup_scr_screen_user_home, LV_SCR_LOAD_ANIM_NONE, 10, 10, true, true);
	if(lvgl_mutex) osMutexRelease(lvgl_mutex);

  /* Infinite loop */
  for(;;)
  {
		/* RX8025T_Task内部会调用LVGL API更新时间显示, 需要互斥锁保护 */
		if(lvgl_mutex) osMutexAcquire(lvgl_mutex, osWaitForever);
		RX8025T_Task();
		if(lvgl_mutex) osMutexRelease(lvgl_mutex);

		/* 更新电池和太阳能电压缓存 (ADC采集, 不涉及LVGL) */
		Battery_UpdateCache();
		Solar_UpdateCache();

    osDelay(1000);
  }
  /* USER CODE END RTC_Task */
}

void Weather_Task(void *argument)
{
  /* USER CODE BEGIN Weather_Task */
	uint8_t jwd_buff[64];//存储经纬度字符串
	CLBS_PosTypeDef pos;

  /* Infinite loop */
  for(;;)
  {
		//等待 0x01 标志位，阻塞等待
    osThreadFlagsWait(0x01, osFlagsWaitAny, osWaitForever);
		if(simcard_ready == 1)
		{
			A7680C_SendAT("AT+CLBS=1\r\n", "+CLBS: 0", 5000,jwd_buff);//读取经纬度
			pos = A7680C_ParseCLBS((char*)jwd_buff);//解析经纬度

			A7680C_HTTP_GetWeatherData(pos.latitude,pos.longitude,&weather_data);//读取天气代码
		}
  }
  /* USER CODE END Weather_Task */
}

/* USER CODE BEGIN Header_DevicePoll_Task */
/**
* @brief Function implementing the DevicePollTask thread.
* @param argument: Not used
* @retval None
*
* 职责（精简版，MQTT初始化已移至StartDefaultTask）:
* 仅在simcard_ready=1时轮询设备状态并上报
*/
/* USER CODE END Header_DevicePoll_Task */
void DevicePoll_Task(void *argument)
{
  /* USER CODE BEGIN DevicePoll_Task */
  RX8025T_Date last_date = {0};  /* 记录上一次的日期，用于检测零点 */
  RX8025T_Date cur_date;
  uint8_t energy_flushed_today = 1;  /* 初始化为1: 防止重启后电量<50%立即触发空结算, 等系统恢复(V>28V+电池≥80%)才重置为0 */

  osDelay(5000);//等待es1642收到帧头错误
	/* 读取ES1642模块MAC地址作为主机唯一标识(异步, 响应在帧回调中保存到g_host_mac) */
	ES1642_ReadMac();
  osDelay(5000);//等待es1642收到帧头错误
  /* 初始化：读取当前日期作为基准 */
  if (RX8025T_GetDate(&last_date) == HAL_OK)
  {
      printf("零点结算初始日期 20%02d-%02d-%02d\r\n",
             last_date.year, last_date.month, last_date.day);
  }
  /* Infinite loop */
  for(;;)
  {
      /* ===== 白天系统恢复 → 重置结算标志, 允许新一天结算 =====
       * 结算(低电量/零点)后energy_flushed_today=1, 只有第二天光照充足
       * (V>28V)且电池充到80%时才重置为0, 确保一天只结算一次。 */
      if (energy_flushed_today == 1 && Battery_GetPercentage() >= 80)
      {
          energy_flushed_today = 0;
          printf("系统恢复(光照充足+电池%d%%), 重置结算标志\r\n", Battery_GetPercentage());
      }

      /* ===== 低电量提前结算(防止夜间锂电池耗尽关机导致RAM数据丢失) =====
       * 晚上太阳能板不发电, 主机靠锂电池维持。如果电池撑不到零点就关机,
       * RAM中的daily_energy_wh会全部丢失。电量<50%时提前结算到SD卡。
       * energy_flushed_today标志防止与零点结算重复执行。 */
      if (!energy_flushed_today && Battery_GetPercentage() < 50)
      {
          printf("低电量(%d%%), 提前执行电量结算\r\n", Battery_GetPercentage());
          daily_energy_flush_to_sd();  /* 将RAM中日累积电量写入SD卡 */
          solar_energy_flush();        /* 太阳能发电量结算并保存到SD卡 */
          energy_flushed_today = 1;    /* 标记今日已结算, 零点不再重复 */
      }

      /* ===== 夜间模式: 只做金丝雀探测, 不轮询从机, 省电 =====
       * 金丝雀探测成功→全员清comm_err+清g_night_mode(在canary内部完成) */
      if (g_night_mode)
      {
          comm_err_canary_probe();  /* 金丝雀探测, 成功时自动退出夜间模式 */
          osDelay(60000);           /* 夜间60秒/轮, 省电 */
          continue;                 /* 跳过正常轮询和osDelay(10000) */
      }

      /* 双重轮询门控:
       * - g_device_manage_mode: 上位机设备管理模式(搜索/绑定时置1), TCP断开自动清零
       * - g_es1642_searching:   ES1642正在搜索(载波总线占用), 搜索完成自动清零
       * 仅当两者均为0时才执行从机轮询, 避免轮询干扰设备搜索和绑定 */
      if(g_device_manage_mode == 0 && g_es1642_searching == 0)
      {
        /* ① MPPT采集+控制一体化(慢速采集→告警扫描→快速P&O控制闭环) */
        device_poll_and_control_all();

        /* ② 太阳能发电量已在daily_energy_flush_to_sd中由各从机kWh累加到g_mppt.energy_kwh,
         *    不再需要在这里外部累加total_energy (保证发电量=Σ从机用电量) */

        /* ⑤ 零点结算检测 */
        if (RX8025T_GetDate(&cur_date) == HAL_OK)
        {
            if (last_date.day != 0 && cur_date.day != last_date.day)
            {
                printf("检测到日期变化(20%02d-%02d-%02d → 20%02d-%02d-%02d)，执行零点结算\r\n",
                      last_date.year, last_date.month, last_date.day,
                      cur_date.year, cur_date.month, cur_date.day);
                /* 如果低电量结算已执行过, 跳过(避免重复清零导致数据丢失) */
                if (!energy_flushed_today)
                {
                    daily_energy_flush_to_sd();  /* 将RAM中日累积电量写入SD卡 */
                    solar_energy_flush();        /* 太阳能发电量结算并保存到SD卡 */
                    energy_flushed_today = 1;  /* 标记今日已结算, 等待次日系统恢复(V>28V+电池≥80%)才重置 */
                }
            }
            last_date = cur_date;
        }
      }
      else if(g_es1642_searching == 1)//就算是搜索期间tcp断开连接了，也会搜索完成之后再启动轮询
      {
        /* 搜索空闲超时检测: 60秒内无新设备被搜索到, 自动停止搜索
         * (解决TCP断连后无人发送停止搜索命令导致搜索永不结束的问题)
         * REPORT_SEARCH_RESULT每次收到新设备会刷新g_last_search_result_tick */
        if((osKernelGetTickCount() - g_last_search_result_tick) > SEARCH_IDLE_TIMEOUT_MS)
        {
            printf("搜索空闲超时(60秒无新设备), 自动停止搜索\r\n");
            tcp_resp_stop_search();
        }
      }

      /* ===== 告警扫描: 每次循环都执行, 不受模式门控限制 =====
       * 确保设备管理模式/搜索模式下也能更新告警页面。
       * 只是遍历RAM中的device_list状态位, 开销极小(无通信)。 */
      alert_scan_devices();

    osDelay(10000);  /* 10秒(控制+采集已在device_poll_and_control_all内完成) */
  }
  /* USER CODE END DevicePoll_Task */
}

/* Callback01 function */
void Callback01(void *argument)
{
  /* USER CODE BEGIN Callback01 */
	osThreadFlagsSet(WeatherTaskHandle, 0x01);
	osTimerStart(weatherTimerHandle,900000);//每15分钟调用一次获取天气函数
  /* USER CODE END Callback01 */
}

/* USER CODE BEGIN Application */
//freertos任务堆栈溢出错误回调函数
void vApplicationStackOverflowHook(TaskHandle_t xTask, char *pcTaskName)
{
    (void)xTask;
    printf("Stack overflow: %s\r\n", pcTaskName);
    taskDISABLE_INTERRUPTS();
    for(;;);
}
/* USER CODE END Application */
